AUTOSAR XML (schema 4-2-1)
package /MICROSAR/BswM_swc
  mode declaration group ESH_Mode: initial-mode=STARTUP
    5 x mode:
      STARTUP
      RUN
      POSTRUN
      WAKEUP
      SHUTDOWN
  mode declaration group ESH_RunRequest: initial-mode=RELEASED
    mode RELEASED
    mode REQUESTED
  data type mapping set BswMMappingSet  # Contains Mapping for ModeDeclarations Groups which are provided by BswM.
    mode-request-type-maps:
      implementation-data-type=BswM_ESH_Mode, mode-group=ESH_Mode
      implementation-data-type=BswM_ESH_RunRequest, mode-group=ESH_RunRequest
package /MICROSAR/BswM_swc/ComponentTypes
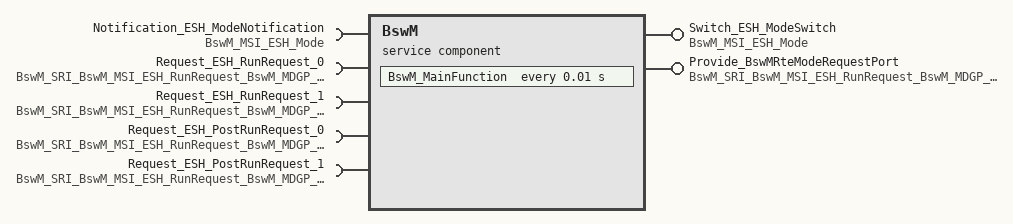
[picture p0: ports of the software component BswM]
  service sw component type BswM: category=SERVICE_COMPONENT
    provide port Switch_ESH_ModeSwitch: provided-interface=BswM_MSI_ESH_Mode
    5 x require port:
      Notification_ESH_ModeNotification: required-interface=BswM_MSI_ESH_Mode
      Request_ESH_RunRequest_0: nonqueued-receiver-com-spec{data-element=BswM_SRI_BswM_MSI_ESH_RunRequest_BswM_MDGP_ESH_RunRequest/requestedMode, handle-out-of-range-status=SILENT, init-value=RELEASED}, required-interface=BswM_SRI_BswM_MSI_ESH_RunRequest_BswM_MDGP_ESH_RunRequest
      Request_ESH_RunRequest_1: nonqueued-receiver-com-spec{data-element=BswM_SRI_BswM_MSI_ESH_RunRequest_BswM_MDGP_ESH_RunRequest/requestedMode, handle-out-of-range-status=SILENT, init-value=RELEASED}, required-interface=BswM_SRI_BswM_MSI_ESH_RunRequest_BswM_MDGP_ESH_RunRequest
      Request_ESH_PostRunRequest_0: nonqueued-receiver-com-spec{data-element=BswM_SRI_BswM_MSI_ESH_RunRequest_BswM_MDGP_ESH_RunRequest/requestedMode, handle-out-of-range-status=SILENT, init-value=RELEASED}, required-interface=BswM_SRI_BswM_MSI_ESH_RunRequest_BswM_MDGP_ESH_RunRequest
      Request_ESH_PostRunRequest_1: nonqueued-receiver-com-spec{data-element=BswM_SRI_BswM_MSI_ESH_RunRequest_BswM_MDGP_ESH_RunRequest/requestedMode, handle-out-of-range-status=SILENT, init-value=RELEASED}, required-interface=BswM_SRI_BswM_MSI_ESH_RunRequest_BswM_MDGP_ESH_RunRequest
    provide port Provide_BswMRteModeRequestPort: nonqueued-sender-com-spec{data-element=BswM_SRI_BswM_MSI_ESH_RunRequest_BswM_MDGP_ESH_RunRequest/requestedMode, init-value=REQUESTED}, provided-interface=BswM_SRI_BswM_MSI_ESH_RunRequest_BswM_MDGP_ESH_RunRequest
    behavior BswMInternalBehavior: data-type-mapping=BswMMappingSet, handle-termination-and-restart=NO-SUPPORT, included-data-type-set=data-type=[BswM_ESH_Mode, BswM_ESH_RunRequest]
      timing event Timer_BswM_MainFunction: start-on-event=BswM_MainFunction, period=0.01
      port-api-options:
        enable-take-address=true, indirect-api=false, port=Switch_ESH_ModeSwitch
        enable-take-address=true, indirect-api=false, port=Notification_ESH_ModeNotification
        enable-take-address=true, indirect-api=false, port=Request_ESH_RunRequest_0
        enable-take-address=true, indirect-api=false, port=Request_ESH_RunRequest_1
        enable-take-address=true, indirect-api=false, port=Request_ESH_PostRunRequest_0
        enable-take-address=true, indirect-api=false, port=Request_ESH_PostRunRequest_1
        enable-take-address=true, indirect-api=false, port=Provide_BswMRteModeRequestPort
      runnable BswM_MainFunction: mode-access-point=Notification_ESH_ModeNotification.BswM_MDGP_ESH_Mode
        data-receive-point-by-arguments:
          4 x access:
            DataReceivePointBswM_MainFunction_Request_ESH_RunRequest_0_requestedMode: accessed-variable=Request_ESH_RunRequest_0.requestedMode
            DataReceivePointBswM_MainFunction_Request_ESH_RunRequest_1_requestedMode: accessed-variable=Request_ESH_RunRequest_1.requestedMode
            DataReceivePointBswM_MainFunction_Request_ESH_PostRunRequest_0_requestedMode: accessed-variable=Request_ESH_PostRunRequest_0.requestedMode
            DataReceivePointBswM_MainFunction_Request_ESH_PostRunRequest_1_requestedMode: accessed-variable=Request_ESH_PostRunRequest_1.requestedMode
        data-send-points:
          access DataSendPointBswM_MainFunction_Provide_BswMRteModeRequestPort_requestedMode: accessed-variable=Provide_BswMRteModeRequestPort.requestedMode
        mode switch point ModeSwitchPointBswM_MainFunction_Switch_ESH_ModeSwitch_BswM_MDGP_ESH_Mode: mode-group=Switch_ESH_ModeSwitch.BswM_MDGP_ESH_Mode
  swc implementation BswMImplementation: programming-language=C, behavior=BswMInternalBehavior
package /MICROSAR/BswM_swc/DataTypes
  impl type BswM_ESH_Mode: compu {0=STARTUP, 1=RUN, 2=POSTRUN, 3=WAKEUP, 4=SHUTDOWN}, range raw 0..255, implementation-data-type=uint8  # Unique value for each user
  impl type BswM_ESH_RunRequest: compu {0=RELEASED, 1=REQUESTED}, range raw 0..255, implementation-data-type=uint8  # Unique value for each user
package /MICROSAR/BswM_swc/Interfaces
  mode switch interface BswM_MSI_ESH_Mode: is-service=true, service-kind=BASIC-SOFTWARE-MODE-MANAGER
    mode group BswM_MDGP_ESH_Mode: type=ESH_Mode
  sender receiver interface BswM_SRI_BswM_MSI_ESH_Mode_BswM_MDGP_ESH_Mode: is-service=true, service-kind=BASIC-SOFTWARE-MODE-MANAGER
    data requestedMode: type=BswM_ESH_Mode
  mode switch interface BswM_MSI_ESH_RunRequest: is-service=true, service-kind=BASIC-SOFTWARE-MODE-MANAGER
    mode group BswM_MDGP_ESH_RunRequest: type=ESH_RunRequest
  sender receiver interface BswM_SRI_BswM_MSI_ESH_RunRequest_BswM_MDGP_ESH_RunRequest: is-service=true, service-kind=BASIC-SOFTWARE-MODE-MANAGER
    data requestedMode: type=BswM_ESH_RunRequest
